VERSION ""

NS_ :

BS_:

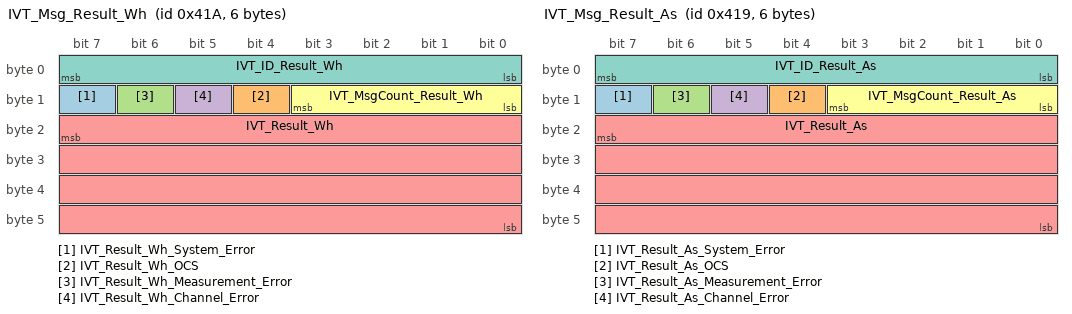
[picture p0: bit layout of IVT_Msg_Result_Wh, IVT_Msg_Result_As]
BO_ 1050 IVT_Msg_Result_Wh: 6 IVT_Mod
 SG_ IVT_Result_Wh_System_Error : 15|1@0+ (1,0) [0|0] "" Vector__XXX
 SG_ IVT_Result_Wh_OCS : 12|1@0+ (1,0) [0|0] "" Vector__XXX
 SG_ IVT_Result_Wh_Measurement_Error : 14|1@0+ (1,0) [0|0] "" Vector__XXX
 SG_ IVT_Result_Wh_Channel_Error : 13|1@0+ (1,0) [0|0] "" Vector__XXX
 SG_ IVT_Result_Wh : 23|32@0- (1,0) [-2147483648|2147483647] "Wh"  Host
 SG_ IVT_MsgCount_Result_Wh : 11|4@0+ (1,0) [0|0] ""  Host
 SG_ IVT_ID_Result_Wh : 7|8@0+ (1,0) [7|7] ""  Host

BO_ 1049 IVT_Msg_Result_As: 6 IVT_Mod
 SG_ IVT_Result_As_System_Error : 15|1@0+ (1,0) [0|0] "" Vector__XXX
 SG_ IVT_Result_As_OCS : 12|1@0+ (1,0) [0|0] "" Vector__XXX
 SG_ IVT_Result_As_Measurement_Error : 14|1@0+ (1,0) [0|0] "" Vector__XXX
 SG_ IVT_Result_As_Channel_Error : 13|1@0+ (1,0) [0|0] "" Vector__XXX
 SG_ IVT_Result_As : 23|32@0- (1,0) [-21474836478|2147483647] "As"  Host
 SG_ IVT_MsgCount_Result_As : 11|4@0+ (1,0) [0|0] ""  Host
 SG_ IVT_ID_Result_As : 7|8@0+ (1,0) [6|6] ""  Host

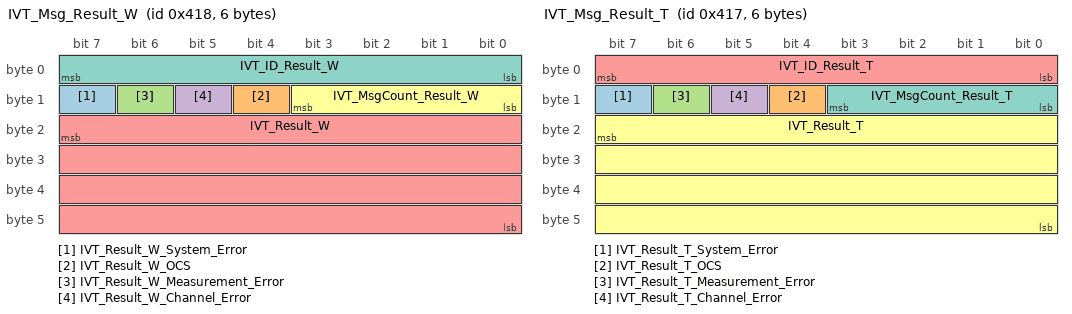
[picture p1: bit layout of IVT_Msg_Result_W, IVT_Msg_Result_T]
BO_ 1048 IVT_Msg_Result_W: 6 IVT_Mod
 SG_ IVT_Result_W_System_Error : 15|1@0+ (1,0) [0|0] "" Vector__XXX
 SG_ IVT_Result_W_OCS : 12|1@0+ (1,0) [0|0] "" Vector__XXX
 SG_ IVT_Result_W_Measurement_Error : 14|1@0+ (1,0) [0|0] "" Vector__XXX
 SG_ IVT_Result_W_Channel_Error : 13|1@0+ (1,0) [0|0] "" Vector__XXX
 SG_ IVT_Result_W : 23|32@0- (1,0) [-2147483648|2147483647] "W"  Host
 SG_ IVT_MsgCount_Result_W : 11|4@0+ (1,0) [0|0] ""  Host
 SG_ IVT_ID_Result_W : 7|8@0+ (1,0) [5|5] ""  Host

BO_ 1047 IVT_Msg_Result_T: 6 IVT_Mod
 SG_ IVT_Result_T_System_Error : 15|1@0+ (1,0) [0|0] "" Vector__XXX
 SG_ IVT_Result_T_OCS : 12|1@0+ (1,0) [0|0] "" Vector__XXX
 SG_ IVT_Result_T_Measurement_Error : 14|1@0+ (1,0) [0|0] "" Vector__XXX
 SG_ IVT_Result_T_Channel_Error : 13|1@0+ (1,0) [0|0] "" Vector__XXX
 SG_ IVT_ID_Result_T : 7|8@0+ (1,0) [4|4] ""  Host
 SG_ IVT_Result_T : 23|32@0- (0.1,0) [-2147483648|2147483647] "\B0C"  Host
 SG_ IVT_MsgCount_Result_T : 11|4@0+ (1,0) [0|0] ""  Host

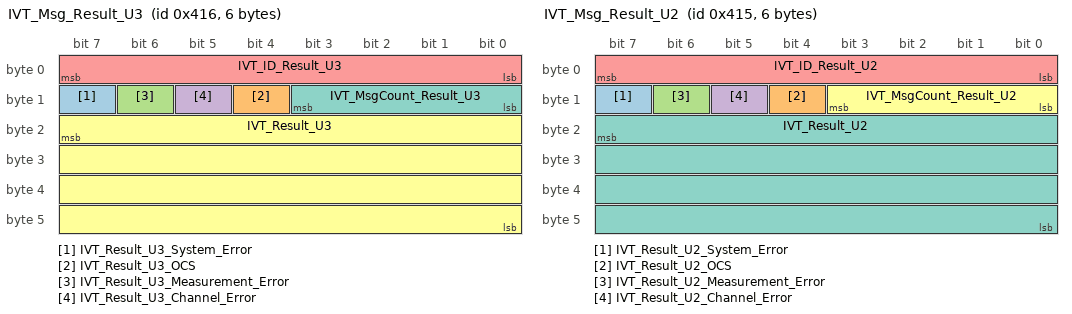
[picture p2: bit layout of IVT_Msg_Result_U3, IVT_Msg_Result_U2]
BO_ 1046 IVT_Msg_Result_U3: 6 IVT_Mod
 SG_ IVT_Result_U3_System_Error : 15|1@0+ (1,0) [0|0] "" Vector__XXX
 SG_ IVT_Result_U3_OCS : 12|1@0+ (1,0) [0|0] "" Vector__XXX
 SG_ IVT_Result_U3_Measurement_Error : 14|1@0+ (1,0) [0|0] "" Vector__XXX
 SG_ IVT_Result_U3_Channel_Error : 13|1@0+ (1,0) [0|0] "" Vector__XXX
 SG_ IVT_ID_Result_U3 : 7|8@0+ (1,0) [3|3] ""  Host
 SG_ IVT_Result_U3 : 23|32@0- (0.001,0) [-2147483648|2147483647] "V"  Host
 SG_ IVT_MsgCount_Result_U3 : 11|4@0+ (1,0) [0|0] ""  Host

BO_ 1045 IVT_Msg_Result_U2: 6 IVT_Mod
 SG_ IVT_Result_U2_System_Error : 15|1@0+ (1,0) [0|0] "" Vector__XXX
 SG_ IVT_Result_U2_OCS : 12|1@0+ (1,0) [0|0] "" Vector__XXX
 SG_ IVT_Result_U2_Measurement_Error : 14|1@0+ (1,0) [0|0] "" Vector__XXX
 SG_ IVT_Result_U2_Channel_Error : 13|1@0+ (1,0) [0|0] "" Vector__XXX
 SG_ IVT_ID_Result_U2 : 7|8@0+ (1,0) [2|2] ""  Host
 SG_ IVT_MsgCount_Result_U2 : 11|4@0+ (1,0) [0|0] ""  Host
 SG_ IVT_Result_U2 : 23|32@0- (0.001,0) [-2147483648|2147483647] "V"  Host

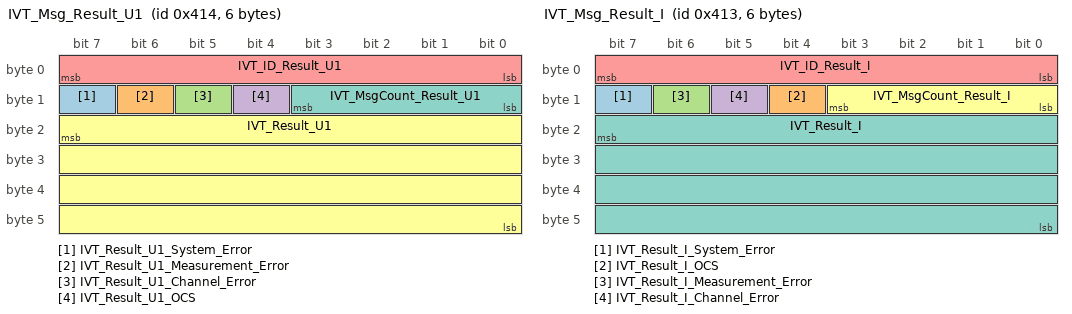
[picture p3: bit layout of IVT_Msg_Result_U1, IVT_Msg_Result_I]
BO_ 1044 IVT_Msg_Result_U1: 6 IVT_Mod
 SG_ IVT_Result_U1_System_Error : 15|1@0+ (1,0) [0|0] "" Vector__XXX
 SG_ IVT_Result_U1_Measurement_Error : 14|1@0+ (1,0) [0|0] "" Vector__XXX
 SG_ IVT_Result_U1_Channel_Error : 13|1@0+ (1,0) [0|0] "" Vector__XXX
 SG_ IVT_Result_U1_OCS : 12|1@0+ (1,0) [0|0] "" Vector__XXX
 SG_ IVT_ID_Result_U1 : 7|8@0+ (1,0) [1|1] ""  Host
 SG_ IVT_Result_U1 : 23|32@0- (0.001,0) [-2147483648|2147483647] "V"  Host
 SG_ IVT_MsgCount_Result_U1 : 11|4@0+ (1,0) [0|0] ""  Host

BO_ 1043 IVT_Msg_Result_I: 6 IVT_Mod
 SG_ IVT_Result_I_System_Error : 15|1@0+ (1,0) [0|0] "" Vector__XXX
 SG_ IVT_Result_I_OCS : 12|1@0+ (1,0) [0|0] "" Vector__XXX
 SG_ IVT_Result_I_Measurement_Error : 14|1@0+ (1,0) [0|0] "" Vector__XXX
 SG_ IVT_Result_I_Channel_Error : 13|1@0+ (1,0) [0|0] "" Vector__XXX
 SG_ IVT_ID_Result_I : 7|8@0+ (1,0) [0|0] ""  Host
 SG_ IVT_MsgCount_Result_I : 11|4@0+ (1,0) [0|0] ""  Host
 SG_ IVT_Result_I : 23|32@0- (0.001,0) [-2147483648|2147483647] "A"  Host
